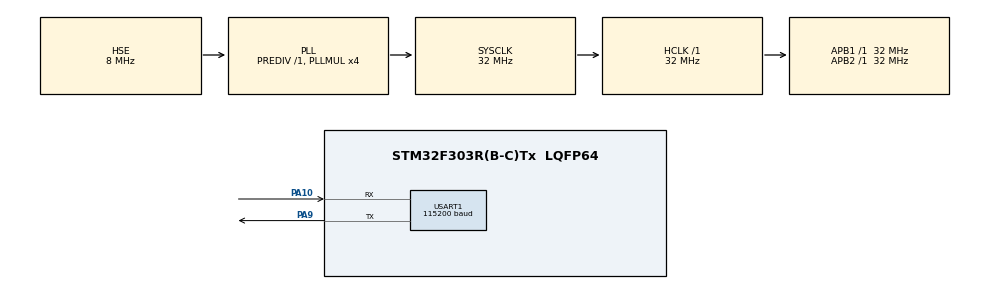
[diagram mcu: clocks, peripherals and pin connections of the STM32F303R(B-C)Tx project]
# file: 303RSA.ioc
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Mcu.Family=STM32F3
Mcu.Name=STM32F303R(B-C)Tx
Mcu.Package=LQFP64
NVIC.PriorityGroup=NVIC_PRIORITYGROUP_4
PA10.Mode=Asynchronous
PA10.Signal=USART1_RX
PA9.Mode=Asynchronous
PA9.Signal=USART1_TX
PF0-OSC_IN.Mode=HSE-External-Oscillator
PF0-OSC_IN.Signal=RCC_OSC_IN
PF1-OSC_OUT.Mode=HSE-External-Oscillator
PF1-OSC_OUT.Signal=RCC_OSC_OUT
ProjectManager.HeapSize=0x200
ProjectManager.StackSize=0x400
ProjectManager.TargetToolchain=STM32CubeIDE
RCC.AHBFreq_Value=32000000
RCC.APB1Freq_Value=32000000
RCC.APB1TimFreq_Value=32000000
RCC.APB2Freq_Value=32000000
RCC.APB2TimFreq_Value=32000000
RCC.CortexFreq_Value=32000000
RCC.HCLKFreq_Value=32000000
RCC.HSE_VALUE=8000000
RCC.HSI_VALUE=8000000
RCC.LSE_VALUE=32768
RCC.PLLMUL=RCC_PLL_MUL4
RCC.PLLSourceVirtual=RCC_PLLSOURCE_HSE
RCC.SYSCLKFreq_VALUE=32000000
RCC.SYSCLKSourceVirtual=RCC_SYSCLKSOURCE_PLLCLK
RCC.USBFreq_Value=32000000
USART1.BaudRate=115200
USART1.VirtualMode-Asynchronous=VM_ASYNC
board=custom

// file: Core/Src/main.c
/* USER CODE BEGIN Header */
/**
  ******************************************************************************
  * @file           : main.c
  * @brief          : Main program body
  ******************************************************************************
  * @attention
  *
  * Copyright (c) 2024 STMicroelectronics.
  * All rights reserved.
  *
  * This software is licensed under terms that can be found in the LICENSE file
  * in the root directory of this software component.
  * If no LICENSE file comes with this software, it is provided AS-IS.
  *
  ******************************************************************************
  */
/* USER CODE END Header */
#include "main.h"

/* USER CODE BEGIN Includes */
#include "rsa.h"
#include <stdint.h>
#include <malloc.h>
#define MESSAGE_LEN 16
/* USER CODE END Includes */

UART_HandleTypeDef huart1;

void SystemClock_Config(void);
static void MX_GPIO_Init(void);
static void MX_USART1_UART_Init(void);

int main(void)
{

  /* USER CODE BEGIN 1 */
  uint16_t len = 0;
  uint8_t message_array[MESSAGE_LEN];
  char* exponent = "0x2717238273472595479053509726616444921567977087848503552842509700413273278854243316590603406748508324260175006287369266487001094026337526844499867124626413";
  char* modulus = "0x4311902652071461882557858520881211379582770437930243004999521314227170237745393932861854820698520469566159792583441703713807235280043465506180681940803211";
  int ret = 0;

  char* out = NULL;
  out = (char*)malloc(sizeof(char)*80);
  if(out == NULL){
  	return 0;
  }

  char* message_string = NULL;
  message_string = (char*)malloc(sizeof(char)*MESSAGE_LEN*2 + 1);
  if(message_string == NULL){
    return 0;
  }

  /* USER CODE END 1 */

  /* MCU Configuration--------------------------------------------------------*/

  /* Reset of all peripherals, Initializes the Flash interface and the Systick. */
  HAL_Init();

  /* Configure the system clock */
  SystemClock_Config();

  /* Initialize all configured peripherals */
  MX_GPIO_Init();
  MX_USART1_UART_Init();

  /* Infinite loop */
  /* USER CODE BEGIN WHILE */
  while (1)
  {
	  char* temp = message_string;

	  ret = HAL_UART_Receive(&huart1, message_array, MESSAGE_LEN, HAL_MAX_DELAY); //receive 16 bytes of plaintext from the serial port
	  int i = 0;
	  for(; i<MESSAGE_LEN; i++){
		  temp += snprintf( temp, 16, "%02X", message_array[i] );
	  }
	  temp[i] = '\0';

	  if(ret==HAL_OK)
	  {
		  __disable_irq();  // disable interrupts
		  HAL_GPIO_WritePin(GPIOA, GPIO_PIN_6, 1); // drive the level high before the operation as a trigger signal
		  len = rsa(message_string, exponent, modulus, out);
		  HAL_GPIO_WritePin(GPIOA, GPIO_PIN_6, 0); // drive the level low after the operation
		  __enable_irq();  // enable interrupts
		  HAL_UART_Transmit(&huart1, out, len, HAL_MAX_DELAY); //send 16 bytes of ciphertext to the serial port
	  }
    /* USER CODE END WHILE */

    /* USER CODE BEGIN 3 */
  }
  free(out);
  free(message_string);
  /* USER CODE END 3 */
}

void SystemClock_Config(void)
{
  RCC_OscInitTypeDef RCC_OscInitStruct = {0};
  RCC_ClkInitTypeDef RCC_ClkInitStruct = {0};
  RCC_PeriphCLKInitTypeDef PeriphClkInit = {0};

  /** Initializes the RCC Oscillators according to the specified parameters
  * in the RCC_OscInitTypeDef structure.
  */
  RCC_OscInitStruct.OscillatorType = RCC_OSCILLATORTYPE_HSE;
  RCC_OscInitStruct.HSEState = RCC_HSE_ON;
  RCC_OscInitStruct.HSEPredivValue = RCC_HSE_PREDIV_DIV1;
  RCC_OscInitStruct.HSIState = RCC_HSI_ON;
  RCC_OscInitStruct.PLL.PLLState = RCC_PLL_ON;
  RCC_OscInitStruct.PLL.PLLSource = RCC_PLLSOURCE_HSE;
  RCC_OscInitStruct.PLL.PLLMUL = RCC_PLL_MUL4;
  if (HAL_RCC_OscConfig(&RCC_OscInitStruct) != HAL_OK)
  {
    Error_Handler();
  }

  /** Initializes the CPU, AHB and APB buses clocks
  */
  RCC_ClkInitStruct.ClockType = RCC_CLOCKTYPE_HCLK|RCC_CLOCKTYPE_SYSCLK
                              |RCC_CLOCKTYPE_PCLK1|RCC_CLOCKTYPE_PCLK2;
  RCC_ClkInitStruct.SYSCLKSource = RCC_SYSCLKSOURCE_PLLCLK;
  RCC_ClkInitStruct.AHBCLKDivider = RCC_SYSCLK_DIV1;
  RCC_ClkInitStruct.APB1CLKDivider = RCC_HCLK_DIV1;
  RCC_ClkInitStruct.APB2CLKDivider = RCC_HCLK_DIV1;

  if (HAL_RCC_ClockConfig(&RCC_ClkInitStruct, FLASH_LATENCY_1) != HAL_OK)
  {
    Error_Handler();
  }
  PeriphClkInit.PeriphClockSelection = RCC_PERIPHCLK_USART1;
  PeriphClkInit.Usart1ClockSelection = RCC_USART1CLKSOURCE_PCLK2;
  if (HAL_RCCEx_PeriphCLKConfig(&PeriphClkInit) != HAL_OK)
  {
    Error_Handler();
  }
}

static void MX_USART1_UART_Init(void)
{

  huart1.Instance = USART1;
  huart1.Init.BaudRate = 115200;
  huart1.Init.WordLength = UART_WORDLENGTH_8B;
  huart1.Init.StopBits = UART_STOPBITS_1;
  huart1.Init.Parity = UART_PARITY_NONE;
  huart1.Init.Mode = UART_MODE_TX_RX;
  huart1.Init.HwFlowCtl = UART_HWCONTROL_NONE;
  huart1.Init.OverSampling = UART_OVERSAMPLING_16;
  huart1.Init.OneBitSampling = UART_ONE_BIT_SAMPLE_DISABLE;
  huart1.AdvancedInit.AdvFeatureInit = UART_ADVFEATURE_NO_INIT;
  if (HAL_UART_Init(&huart1) != HAL_OK)
  {
    Error_Handler();
  }

}

static void MX_GPIO_Init(void)
{

  /* GPIO Ports Clock Enable */
  __HAL_RCC_GPIOF_CLK_ENABLE();
  __HAL_RCC_GPIOA_CLK_ENABLE();

}

void Error_Handler(void)
{
  __disable_irq();
  while (1)
  {
  }
}
